# R7FA8D1BH register map
Vendor: Renesas; Series: RA8; File version: 1.2
CPU: CM85 r0p0, little endian, MPU, FPU, VTOR, 4 interrupt priority bits
Registers are 32-bit, read-write, reset 0x0 unless marked. A register's access mark holds for its fields unless they carry their own. Offsets are from the block's base; [hi:lo] are bit positions.

## PSCU — Peripheral Security Control Unit
Base 0x40204000
Same registers: PSCU_NS 0x50204000
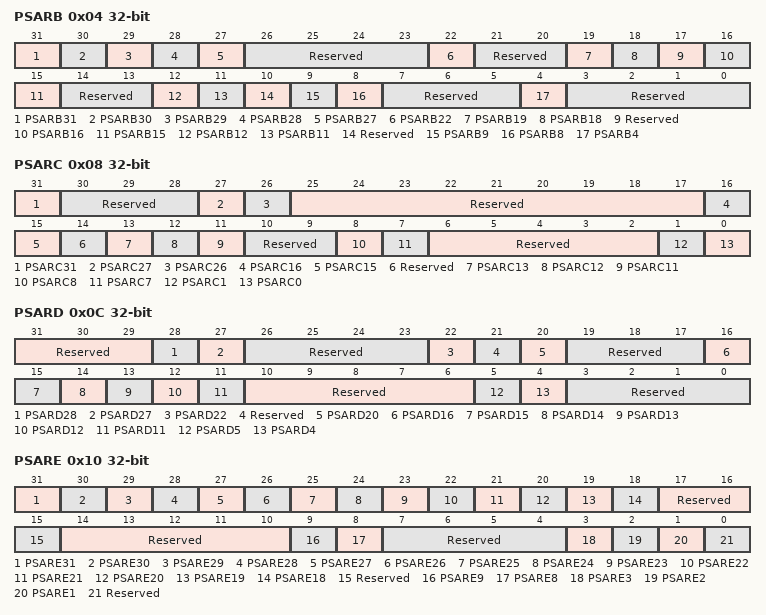
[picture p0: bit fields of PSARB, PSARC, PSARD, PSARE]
0x04 PSARB — Peripheral Security Attribution Register B
  [31] PSARB31 — Serial Communication Interface 0 Security Attribution
  [30] PSARB30 — Serial Communication Interface 1 Security Attribution
  [29] PSARB29 — Serial Communication Interface 2 Security Attribution
  [28] PSARB28 — Serial Communication Interface 3 Security Attribution
  [27] PSARB27 — Serial Communication Interface 4 Security Attribution
  [26:23] Reserved — These bits are read as 0000. The write value should be 0000.
  [22] PSARB22 — Serial Communication Interface 9 Security Attribution
  [21:20] Reserved — These bits are read as 00. The write value should be 00.
  [19] PSARB19 — Serial Peripheral Interface 0 Security Attribution
  [18] PSARB18 — Serial Peripheral Interface 1 Security Attribution
  [17] Reserved — This bit is read as 0. The write value should be 0.
  [16] PSARB16 — Octa Memory Controller Security Attribution
  [15] PSARB15 — ETHER0/EDMAC0 Controller Security Attribution
  [14:13] Reserved — These bits are read as 00. The write value should be 00.
  [12] PSARB12 — Universal Serial Bus 2.0 HS Interface 0 Security Attribution
  [11] PSARB11 — Universal Serial Bus 2.0 FS Interface 0 Security Attribution
  [10] Reserved — This bit is read as 0. The write value should be 0.
  [9] PSARB9 — I2C Bus Interface 0 Security Attribution
  [8] PSARB8 — I2C Bus Interface 1 Security Attribution
  [7:5] Reserved — These bits are read as 000. The write value should be 000.
  [4] PSARB4 — I3C Bus Interface 2 Security Attribution
  [3:0] Reserved — These bits are read as 0000. The write value should be 0000.
0x08 PSARC — Peripheral Security Attribution Register C
  [31] PSARC31 — SHIP Security Attribution
  [30:28] Reserved — These bits are read as 000. The write value should be 000.
  [27] PSARC27 — Controller Area Network with Flexible Data-Rate 0 Security Attribution
  [26] PSARC26 — Controller Area Network with Flexible Data-Rate 1 Security Attribution
  [25:17] Reserved — These bits are read as 000000000. The write value should be 000000000.
  [16] PSARC16 — CEU Security Attribution
  [15] PSARC15 — Graph-ic(GLCDC,MIPI,DRW,JPEG) Security Attribution
  [14] Reserved — This bit is read as 0. The write value should be 0.
  [13] PSARC13 — Data Operation Circuit Security Attribution
  [12] PSARC12 — Secure Digital Host IF 0 Security Attribution
  [11] PSARC11 — Secure Digital Host IF 1 Security Attribution
  [10:9] Reserved — These bits are read as 00. The write value should be 00.
  [8] PSARC8 — Serial Sound Interface Enhanced (channel 0) Security Attribution
  [7] PSARC7 — Serial Sound Interface Enhanced (channel 1) Security Attribution
  [6:2] Reserved — These bits are read as 00000. The write value should be 00000.
  [1] PSARC1 — Cyclic Redundancy Check Calculator Security Attribution
  [0] PSARC0 — Clock Frequency Accuracy Measurement Circuit Security Attribution
0x0C PSARD — Peripheral Security Attribution Register D
  [31:29] Reserved — These bits are read as 000. The write value should be 000.
  [28] PSARD28 — High speed analog Comparator 0 Security Attribution
  [27] PSARD27 — High speed analog Comparator 1 Security Attribution
  [26:23] Reserved — These bits are read as 0000. The write value should be 0000.
  [22] PSARD22 — Temperature Sensor Security Attribution
  [21] Reserved — This bit is read as 0. The write value should be 0.
  [20] PSARD20 — 12-Bit D/A Converter Security Attribution
  [19:17] Reserved — These bits are read as 000. The write value should be 000.
  [16] PSARD16 — 12-Bit A/D 0 Converter Security Attribution
    0=Secure; 1=NonSecure
  [15] PSARD15 — 12-Bit A/D 1 Converter Security Attribution
    0=Secure; 1=NonSecure
  [14] PSARD14 — Port Output Enable for GPT Group 0 Security Attribution
  [13] PSARD13 — Port Output Enable for GPT Group 1 Security Attribution
  [12] PSARD12 — Port Output Enable for GPT Group 2 Security Attribution
  [11] PSARD11 — Port Output Enable for GPT Group 3 Security Attribution
  [10:6] Reserved — These bits are read as 00000. The write value should be 00000.
  [5] PSARD5 — Asynchronous General Purpose Timer 0 Security Attribution
  [4] PSARD4 — Asynchronous General Purpose Timer 1 Security Attribution
  [3:0] Reserved — These bits are read as 0000. The write value should be 0000.
0x10 PSARE — Peripheral Security Attribution Register E
  [31] PSARE31 — General PWM Timer channel0 Security Attribution
  [30] PSARE30 — General PWM Timer channel1 Security Attribution
  [29] PSARE29 — General PWM Timer channel2 Security Attribution
  [28] PSARE28 — General PWM Timer channel3 Security Attribution
  [27] PSARE27 — General PWM Timer channel4 Security Attribution
  [26] PSARE26 — General PWM Timer channel5 Security Attribution
  [25] PSARE25 — General PWM Timer channel6 Security Attribution
  [24] PSARE24 — General PWM Timer channel7 Security Attribution
  [23] PSARE23 — General PWM Timer channel8 Security Attribution
  [22] PSARE22 — General PWM Timer channel9 Security Attribution
  [21] PSARE21 — General PWM Timer channel10 Security Attribution
  [20] PSARE20 — General PWM Timer channel11 Security Attribution
  [19] PSARE19 — General PWM Timer channel12 Security Attribution
  [18] PSARE18 — General PWM Timer channel13 Security Attribution
  [17:16] Reserved — These bits are read as 00. The write value should be 00.
  [15] Reserved — This bit is read as 0. The write value should be 0.
  [14:10] Reserved — These bits are read as 00000. The write value should be 00000.
  [9] PSARE9 — ULPT0 Security Attribution
  [8] PSARE8 — ULPT1 Security Attribution
  [7:4] Reserved — These bits are read as 0000. The write value should be 0000.
  [3] PSARE3 — Real Time Clock Security Attribution
  [2] PSARE2 — Independent Watchdog Timer Security Attribution
  [1] PSARE1 — WDT0 Security Attribution
    0=Secure; 1=NonSecure
  [0] Reserved — This bit is read as 0. The write value should be 0.
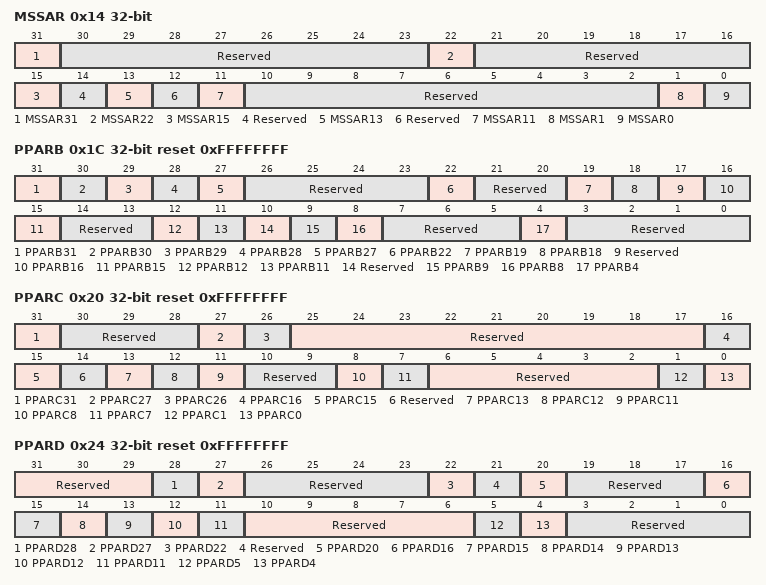
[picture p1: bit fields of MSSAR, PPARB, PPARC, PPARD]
0x14 MSSAR — Module Stop Security Attribution Register
  [31] MSSAR31 — ELC clock stop Security Attribution
    0=Secure; 1=Non-Secure
  [30:23] Reserved — These bits are read as 00000000. The write value should be 00000000.
  [22] MSSAR22 — DMAC0/DTC0 Clock Stop Security Attribution
  [21:16] Reserved — These bits are read as 000000. The write value should be 000000.
  [15] MSSAR15 — Standby RAM Clock Stop Security Attribution
    0=Secure; 1=Non-Secure
  [14] Reserved — This bit is read as 0. The write value should be 0.
  [13] MSSAR13 — STCM0 Security Attribution
    0=Secure; 1=Non-Secure
  [12] Reserved — This bit is read as 0. The write value should be 0.
  [11] MSSAR11 — CTCM0 Security Attribution
    0=Secure; 1=Non-Secure
  [10:2] Reserved — These bits are read as 000000000. The write value should be 000000000.
  [1] MSSAR1 — SRAM1 Clock Stop Security Attribution
    0=Secure; 1=Non-Secure
  [0] MSSAR0 — SRAM0 Clock Stop Security Attribution
    0=Secure; 1=Non-Secure
0x1C PPARB reset 0xFFFFFFFF — Peripheral Privilege Attribution Register B
  [31] PPARB31 — Serial Communication Interface 0 Privilege Attribution
  [30] PPARB30 — Serial Communication Interface 1 Privilege Attribution
  [29] PPARB29 — Serial Communication Interface 2 Privilege Attribution
  [28] PPARB28 — Serial Communication Interface 3 Privilege Attribution
  [27] PPARB27 — Serial Communication Interface 4 Privilege Attribution
  [26:23] Reserved — These bits are read as 1111. The write value should be 1111.
  [22] PPARB22 — Serial Communication Interface 9 Privilege Attribution
  [21:20] Reserved — These bits are read as 11. The write value should be 11.
  [19] PPARB19 — Serial Peripheral Interface 0 Privilege Attribution
  [18] PPARB18 — Serial Peripheral Interface 1 Privilege Attribution
  [17] Reserved — This bit is read as 1. The write value should be 1.
  [16] PPARB16 — Octa Memory Controller Privilege Attribution
  [15] PPARB15 — ETHER0/EDMAC0 Controller Privilege Attribution
  [14:13] Reserved — These bits are read as 11. The write value should be 11.
  [12] PPARB12 — Universal Serial Bus 2.0 HS Interface 0 Privilege Attribution
  [11] PPARB11 — Universal Serial Bus 2.0 FS Interface 0 Privilege Attribution
  [10] Reserved — This bit is read as 1. The write value should be 1.
  [9] PPARB9 — I2C Bus Interface 0 Privilege Attribution
  [8] PPARB8 — I2C Bus Interface 1 Privilege Attribution
  [7:5] Reserved — These bits are read as 111. The write value should be 111.
  [4] PPARB4 — I3C Bus Interface 2 Privilege Attribution
  [3:0] Reserved — These bits are read as 1111. The write value should be 1111.
0x20 PPARC reset 0xFFFFFFFF — Peripheral Privilege Attribution Register C
  [31] PPARC31 — SHIP Privilege Attribution
  [30:28] Reserved — These bits are read as 111. The write value should be 111.
  [27] PPARC27 — Controller Area Network with Flexible Data-Rate 0 Privilege Attribution
  [26] PPARC26 — Controller Area Network with Flexible Data-Rate 1 Privilege Attribution
  [25:17] Reserved — These bits are read as 111111111. The write value should be 111111111.
  [16] PPARC16 — CEU Privilege Attribution
  [15] PPARC15 — Graph-ic(GLCDC,MIPI,DRW,JPEG) Privilege Attribution
  [14] Reserved — This bit is read as 1. The write value should be 1.
  [13] PPARC13 — Data Operation Circuit Privilege Attribution
  [12] PPARC12 — Privilege Digital Host IF 0 Privilege Attribution
  [11] PPARC11 — Privilege Digital Host IF 1 Privilege Attribution
  [10:9] Reserved — These bits are read as 11. The write value should be 11.
  [8] PPARC8 — Serial Sound Interface Enhanced (channel 0) Privilege Attribution
  [7] PPARC7 — Serial Sound Interface Enhanced (channel 1) Privilege Attribution
  [6:2] Reserved — These bits are read as 11111. The write value should be 11111.
  [1] PPARC1 — Cyclic Redundancy Check Calculator Privilege Attribution
  [0] PPARC0 — Clock Frequency Accuracy Measurement Circuit Privilege Attribution
0x24 PPARD reset 0xFFFFFFFF — Peripheral Privilege Attribution Register D
  [31:29] Reserved — These bits are read as 111. The write value should be 111.
  [28] PPARD28 — High speed analog Comparator 0 Privilege Attribution
  [27] PPARD27 — High speed analog Comparator 1 Privilege Attribution
  [26:23] Reserved — These bits are read as 1111. The write value should be 1111.
  [22] PPARD22 — Temperature Sensor Privilege Attribution
  [21] Reserved — This bit is read as 1. The write value should be 1.
  [20] PPARD20 — 12-Bit D/A Converter Privilege Attribution
  [19:17] Reserved — These bits are read as 111. The write value should be 111.
  [16] PPARD16 — 12-Bit A/D 0 Converter Privilege Attribution
    0=Privilege; 1=Any Privilege
  [15] PPARD15 — 12-Bit A/D 1 Converter Privilege Attribution
    0=Privilege; 1=Any Privilege
  [14] PPARD14 — Port Output Enable for GPT Group 0 Privilege Attribution
  [13] PPARD13 — Port Output Enable for GPT Group 1 Privilege Attribution
  [12] PPARD12 — Port Output Enable for GPT Group 2 Privilege Attribution
  [11] PPARD11 — Port Output Enable for GPT Group 3 Privilege Attribution
  [10:6] Reserved — These bits are read as 11111. The write value should be 11111.
  [5] PPARD5 — Asynchronous General Purpose Timer 0 Privilege Attribution
  [4] PPARD4 — Asynchronous General Purpose Timer 1 Privilege Attribution
  [3:0] Reserved — These bits are read as 1111. The write value should be 1111.
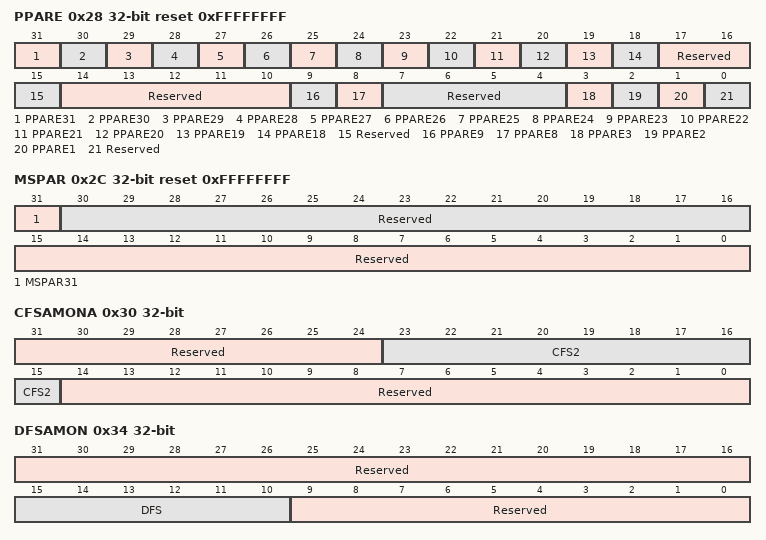
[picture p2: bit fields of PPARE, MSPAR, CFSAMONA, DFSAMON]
0x28 PPARE reset 0xFFFFFFFF — Peripheral Privilege Attribution Register E
  [31] PPARE31 — General PWM Timer channel0 Privilege Attribution
  [30] PPARE30 — General PWM Timer channel1 Privilege Attribution
  [29] PPARE29 — General PWM Timer channel2 Privilege Attribution
  [28] PPARE28 — General PWM Timer channel3 Privilege Attribution
  [27] PPARE27 — General PWM Timer channel4 Privilege Attribution
  [26] PPARE26 — General PWM Timer channel5 Privilege Attribution
  [25] PPARE25 — General PWM Timer channel6 Privilege Attribution
  [24] PPARE24 — General PWM Timer channel7 Privilege Attribution
  [23] PPARE23 — General PWM Timer channel8 Privilege Attribution
  [22] PPARE22 — General PWM Timer channel9 Privilege Attribution
  [21] PPARE21 — General PWM Timer channel10 Privilege Attribution
  [20] PPARE20 — General PWM Timer channel11 Privilege Attribution
  [19] PPARE19 — General PWM Timer channel12 Privilege Attribution
  [18] PPARE18 — General PWM Timer channel13 Privilege Attribution
  [17:16] Reserved — These bits are read as 11. The write value should be 11.
  [15] Reserved — This bit is read as 1. The write value should be 1.
  [14:10] Reserved — These bits are read as 11111. The write value should be 11111.
  [9] PPARE9 — ULPT0 Privilege Attribution
  [8] PPARE8 — ULPT1 Privilege Attribution
  [7:4] Reserved — These bits are read as 1111. The write value should be 1111.
  [3] PPARE3 — Real Time Clock Privilege Attribution
  [2] PPARE2 — Independent Watchdog Timer Privilege Attribution
  [1] PPARE1 — Watchdog Timer0 Privilege Attribution
  [0] Reserved — This bit is read as 1. The write value should be 1.
0x2C MSPAR reset 0xFFFFFFFF — Module Stop Privilege Attribution Register
  [31] MSPAR31 — ELC clock stop Privilege Attribution
    0=Privilege; 1=Non-Privilege
  [30:16] Reserved — These bits are read as 111111111111111. The write value should be 111111111111111.
  [15:0] Reserved — These bits are read as 1111111111111111. The write value should be 1111111111111111.
0x30 CFSAMONA ro (reset mask 0xFF007FFF) — Code Flash Security Attribution Monitor Register A
  [31:24] Reserved — These bits are read as 00000000.
  [23:15] CFS2 — Code Flash Secure area
  [14:0] Reserved — These bits are read as 000000000000000.
0x34 DFSAMON ro (reset mask 0xFFFF03FF) — Data Flash Security Attribution Monitor Register
  [31:16] Reserved — These bits are read as 0000000000000000.
  [15:10] DFS — Data flash Secure area
  [9:0] Reserved — These bits are read as 0000000000.
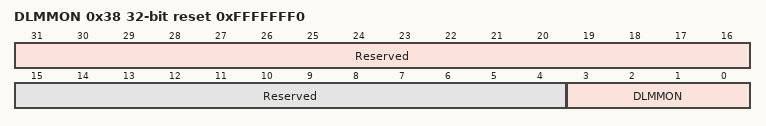
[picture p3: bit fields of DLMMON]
0x38 DLMMON ro reset 0xFFFFFFF0 (reset mask 0xFFFFFFF0) — Device Lifecycle Management State Monitor Register
  [31:16] Reserved — These bits are read as 1111111111111111.
  [15:4] Reserved — These bits are read as 111111111111.
  [3:0] DLMMON — Device Lifecycle Management State Monitor
